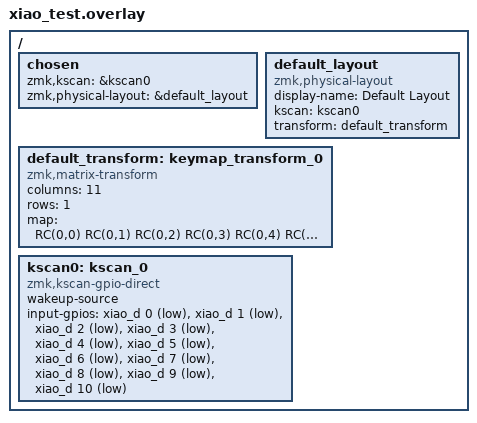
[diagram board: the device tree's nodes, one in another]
#include <dt-bindings/zmk/matrix_transform.h>

/ {
    chosen {
        zmk,kscan = &kscan0;
        zmk,physical-layout = &default_layout;
    };

    default_layout: default_layout {
        compatible = "zmk,physical-layout";
        display-name = "Default Layout";
        kscan = <&kscan0>;
        transform = <&default_transform>;
    };

    default_transform: keymap_transform_0 {
        compatible = "zmk,matrix-transform";
        columns = <11>;
        rows = <1>;
        map = <
            RC(0,0) RC(0,1) RC(0,2) RC(0,3) RC(0,4) RC(0,5) RC(0,6) RC(0,7) RC(0,8) RC(0,9) RC(0,10)
        >;
    };

    kscan0: kscan_0 {
        compatible = "zmk,kscan-gpio-direct";
        wakeup-source;
        input-gpios
            = <&xiao_d 0 (GPIO_ACTIVE_LOW | GPIO_PULL_UP)>
            , <&xiao_d 1 (GPIO_ACTIVE_LOW | GPIO_PULL_UP)>
            , <&xiao_d 2 (GPIO_ACTIVE_LOW | GPIO_PULL_UP)>
            , <&xiao_d 3 (GPIO_ACTIVE_LOW | GPIO_PULL_UP)>
            , <&xiao_d 4 (GPIO_ACTIVE_LOW | GPIO_PULL_UP)>
            , <&xiao_d 5 (GPIO_ACTIVE_LOW | GPIO_PULL_UP)>
            , <&xiao_d 6 (GPIO_ACTIVE_LOW | GPIO_PULL_UP)>
            , <&xiao_d 7 (GPIO_ACTIVE_LOW | GPIO_PULL_UP)>
            , <&xiao_d 8 (GPIO_ACTIVE_LOW | GPIO_PULL_UP)>
            , <&xiao_d 9 (GPIO_ACTIVE_LOW | GPIO_PULL_UP)>
            , <&xiao_d 10 (GPIO_ACTIVE_LOW | GPIO_PULL_UP)>
            ;
    };
};
